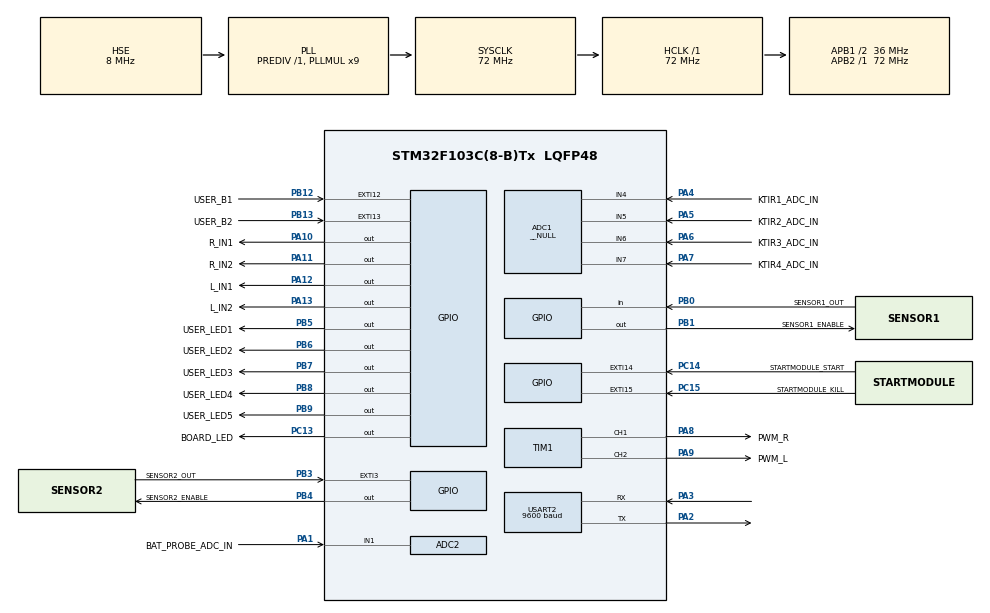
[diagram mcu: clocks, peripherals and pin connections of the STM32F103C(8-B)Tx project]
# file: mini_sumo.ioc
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Mcu.Family=STM32F1
ADC1.ContinuousConvMode=ENABLE
ADC2.Channel-0\#ChannelRegularConversion=ADC_CHANNEL_1
PA6.GPIO_Label=KTIR3_ADC_IN
PB0.GPIO_Label=SENSOR1_OUT
PB6.GPIO_Label=USER_LED2
PB13.GPIO_Label=USER_B2
PB13.Signal=GPXTI13
PC15-OSC32_OUT.GPIO_Label=STARTMODULE_KILL
RCC.SYSCLKSource=RCC_SYSCLKSOURCE_PLLCLK
ProjectManager.StackSize=0x400
PD1-OSC_OUT.Signal=RCC_OSC_OUT
PA12.Signal=GPIO_Output
ADC1.Mode=__NULL
RCC.HCLKFreq_Value=72000000
RCC.APB2TimFreq_Value=72000000
PB6.Signal=GPIO_Output
Dma.ADC1.0.Direction=DMA_PERIPH_TO_MEMORY
Dma.ADC1.0.MemDataAlignment=DMA_MDATAALIGN_HALFWORD
RCC.AHBFreq_Value=72000000
RCC.PLLMUL=RCC_PLL_MUL9
PB12.GPIO_Label=USER_B1
TIM1.Channel-PWM\ Generation1\ CH1=TIM_CHANNEL_1
PB1.GPIO_Label=SENSOR1_ENABLE
Dma.ADC1.0.PeriphInc=DMA_PINC_DISABLE
PA10.GPIO_Label=R_IN1
PB7.Signal=GPIO_Output
PA8.Signal=S_TIM1_CH1
PB7.GPIO_Label=USER_LED3
Mcu.Package=LQFP48
PB9.Signal=GPIO_Output
PB1.Signal=GPIO_Output
PA6.Signal=ADCx_IN6
USART2.VirtualMode=VM_ASYNC
PA10.Signal=GPIO_Output
ADC2.SamplingTime-0\#ChannelRegularConversion=ADC_SAMPLETIME_1CYCLE_5
SH.ADCx_IN1.0=ADC2_IN1,IN1
PB5.GPIO_Label=USER_LED1
RCC.APB1TimFreq_Value=72000000
PC14-OSC32_IN.GPIO_Label=STARTMODULE_START
ADC2.Rank-0\#ChannelRegularConversion=1
Dma.Request0=ADC1
PA4.GPIO_Label=KTIR1_ADC_IN
PB4.Signal=GPIO_Output
PA3.Signal=USART2_RX
PB3.GPIO_Label=SENSOR2_OUT
RCC.PLLSourceVirtual=RCC_PLLSOURCE_HSE
Dma.ADC1.0.Instance=DMA1_Channel1
PD1-OSC_OUT.Mode=HSE-External-Oscillator
PB9.GPIO_Label=USER_LED5
SH.ADCx_IN6.0=ADC1_IN6,IN6
PA9.GPIO_Label=PWM_L
PC13-TAMPER-RTC.Signal=GPIO_Output
PA11.GPIO_Label=R_IN2
PD0-OSC_IN.Signal=RCC_OSC_IN
RCC.APB1CLKDivider=RCC_HCLK_DIV2
PC14-OSC32_IN.Signal=GPXTI14
VP_SYS_VS_ND.Mode=No_Debug
NVIC.USART2_IRQn=true\:0\:0\:false\:false\:true\:true\:true
USART2.BaudRate=9600
PA12.GPIO_Label=L_IN1
RCC.ADCPresc=RCC_ADCPCLK2_DIV6
PA3.Mode=Asynchronous
PA13.Signal=GPIO_Output
PB8.GPIO_Label=USER_LED4
Dma.ADC1.0.PeriphDataAlignment=DMA_PDATAALIGN_HALFWORD
PA8.GPIO_Label=PWM_R
SH.S_TIM1_CH1.0=TIM1_CH1,PWM Generation1 CH1
ProjectManager.TargetToolchain=STM32CubeIDE
SH.ADCx_IN7.0=ADC1_IN7,IN7
Dma.ADC1.0.Mode=DMA_CIRCULAR
Dma.ADC1.0.Priority=DMA_PRIORITY_LOW
PA9.Signal=S_TIM1_CH2
ADC1.Channel-1\#ChannelRegularConversion=ADC_CHANNEL_4
TIM1.Channel-PWM\ Generation2\ CH2=TIM_CHANNEL_2
RCC.USBFreq_Value=72000000
PC15-OSC32_OUT.Signal=GPXTI15
PA1.Signal=ADCx_IN1
PD0-OSC_IN.Mode=HSE-External-Oscillator
PA5.Signal=ADCx_IN5
board=custom
PC13-TAMPER-RTC.GPIO_Label=BOARD_LED
RCC.APB2Freq_Value=72000000
PB4.GPIO_Label=SENSOR2_ENABLE
SH.S_TIM1_CH2.0=TIM1_CH2,PWM Generation2 CH2
PA1.GPIO_Label=BAT_PROBE_ADC_IN
SH.ADCx_IN4.0=ADC1_IN4,IN4
ADC1.NbrOfConversion=1
Mcu.Name=STM32F103C(8-B)Tx
PA2.Signal=USART2_TX
PA13.GPIO_Label=L_IN2
PB3.Signal=GPXTI3
PA4.Signal=ADCx_IN4
ADC1.SamplingTime-1\#ChannelRegularConversion=ADC_SAMPLETIME_239CYCLES_5
RCC.SYSCLKFreq_VALUE=72000000
PB5.Signal=GPIO_Output
PA7.GPIO_Label=KTIR4_ADC_IN
ADC1.master=1
PA5.GPIO_Label=KTIR2_ADC_IN
ADC2.NbrOfConversionFlag=1
ADC1.Rank-1\#ChannelRegularConversion=1
PA11.Signal=GPIO_Output
Dma.ADC1.0.MemInc=DMA_MINC_ENABLE
ProjectManager.HeapSize=0x200
SH.ADCx_IN5.0=ADC1_IN5,IN5
NVIC.PriorityGroup=NVIC_PRIORITYGROUP_4
ADC1.NbrOfConversionFlag=1
PA2.Mode=Asynchronous
PB8.Signal=GPIO_Output
NVIC.DMA1_Channel1_IRQn=true\:0\:0\:false\:false\:true\:false\:true
RCC.APB1Freq_Value=36000000
PB0.Signal=GPIO_Input
PB12.Signal=GPXTI12
PB0.GPIO_PuPd=GPIO_PULLUP
PA7.Signal=ADCx_IN7

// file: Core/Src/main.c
/* USER CODE BEGIN Header */
/**
  ******************************************************************************
  * @file           : main.c
  * @brief          : Main program body
  ******************************************************************************
  * @attention
  *
  * <h2><center>&copy; Copyright (c) 2021 STMicroelectronics.
  * All rights reserved.</center></h2>
  *
  * This software component is licensed by ST under BSD 3-Clause license,
  * the "License"; You may not use this file except in compliance with the
  * License. You may obtain a copy of the License at:
  *                        opensource.org/licenses/BSD-3-Clause
  *
  ******************************************************************************
  */
/* USER CODE END Header */
#include "main.h"

/* USER CODE BEGIN Includes */

#include <stdio.h>

/* USER CODE END Includes */

ADC_HandleTypeDef hadc1;
ADC_HandleTypeDef hadc2;
DMA_HandleTypeDef hdma_adc1;

TIM_HandleTypeDef htim1;

UART_HandleTypeDef huart2;

void SystemClock_Config(void);
static void MX_GPIO_Init(void);
static void MX_DMA_Init(void);
static void MX_ADC1_Init(void);
static void MX_USART2_UART_Init(void);
static void MX_TIM1_Init(void);
static void MX_ADC2_Init(void);
/* USER CODE BEGIN PFP */

int
_write(int file, uint8_t *ptr, int len) {
	HAL_UART_Transmit_IT(&huart2, ptr, len);
	return len;
}

/* USER CODE END PFP */

int main(void)
{

  /* MCU Configuration--------------------------------------------------------*/

  /* Reset of all peripherals, Initializes the Flash interface and the Systick. */
  HAL_Init();

  /* Configure the system clock */
  SystemClock_Config();

  /* Initialize all configured peripherals */
  MX_GPIO_Init();
  MX_DMA_Init();
  MX_ADC1_Init();
  MX_USART2_UART_Init();
  MX_TIM1_Init();
  MX_ADC2_Init();
  /* USER CODE BEGIN 2 */
  HAL_GPIO_WritePin(SENSOR1_ENABLE_GPIO_Port, SENSOR1_ENABLE_Pin, 1);
  uint8_t flag = 0;
  /* USER CODE END 2 */

  /* Infinite loop */
  /* USER CODE BEGIN WHILE */
  while (1)
  {

	  if (HAL_GPIO_ReadPin(SENSOR1_OUT_GPIO_Port, SENSOR1_OUT_Pin) == 0) {
		  flag = 1;
	  }

	  HAL_Delay(1000);
	  if (flag) {
	  HAL_GPIO_TogglePin(BOARD_LED_GPIO_Port, BOARD_LED_Pin);
	  }

    /* USER CODE END WHILE */

  }
}

void SystemClock_Config(void)
{
  RCC_OscInitTypeDef RCC_OscInitStruct = {0};
  RCC_ClkInitTypeDef RCC_ClkInitStruct = {0};
  RCC_PeriphCLKInitTypeDef PeriphClkInit = {0};

  /** Initializes the RCC Oscillators according to the specified parameters
  * in the RCC_OscInitTypeDef structure.
  */
  RCC_OscInitStruct.OscillatorType = RCC_OSCILLATORTYPE_HSE;
  RCC_OscInitStruct.HSEState = RCC_HSE_ON;
  RCC_OscInitStruct.HSEPredivValue = RCC_HSE_PREDIV_DIV1;
  RCC_OscInitStruct.HSIState = RCC_HSI_ON;
  RCC_OscInitStruct.PLL.PLLState = RCC_PLL_ON;
  RCC_OscInitStruct.PLL.PLLSource = RCC_PLLSOURCE_HSE;
  RCC_OscInitStruct.PLL.PLLMUL = RCC_PLL_MUL9;
  if (HAL_RCC_OscConfig(&RCC_OscInitStruct) != HAL_OK)
  {
    Error_Handler();
  }
  /** Initializes the CPU, AHB and APB buses clocks
  */
  RCC_ClkInitStruct.ClockType = RCC_CLOCKTYPE_HCLK|RCC_CLOCKTYPE_SYSCLK
                              |RCC_CLOCKTYPE_PCLK1|RCC_CLOCKTYPE_PCLK2;
  RCC_ClkInitStruct.SYSCLKSource = RCC_SYSCLKSOURCE_PLLCLK;
  RCC_ClkInitStruct.AHBCLKDivider = RCC_SYSCLK_DIV1;
  RCC_ClkInitStruct.APB1CLKDivider = RCC_HCLK_DIV2;
  RCC_ClkInitStruct.APB2CLKDivider = RCC_HCLK_DIV1;

  if (HAL_RCC_ClockConfig(&RCC_ClkInitStruct, FLASH_LATENCY_2) != HAL_OK)
  {
    Error_Handler();
  }
  PeriphClkInit.PeriphClockSelection = RCC_PERIPHCLK_ADC;
  PeriphClkInit.AdcClockSelection = RCC_ADCPCLK2_DIV6;
  if (HAL_RCCEx_PeriphCLKConfig(&PeriphClkInit) != HAL_OK)
  {
    Error_Handler();
  }
}

static void MX_ADC1_Init(void)
{

  ADC_ChannelConfTypeDef sConfig = {0};

  /** Common config
  */
  hadc1.Instance = ADC1;
  hadc1.Init.ScanConvMode = ADC_SCAN_DISABLE;
  hadc1.Init.ContinuousConvMode = ENABLE;
  hadc1.Init.DiscontinuousConvMode = DISABLE;
  hadc1.Init.ExternalTrigConv = ADC_SOFTWARE_START;
  hadc1.Init.DataAlign = ADC_DATAALIGN_RIGHT;
  hadc1.Init.NbrOfConversion = 1;
  if (HAL_ADC_Init(&hadc1) != HAL_OK)
  {
    Error_Handler();
  }
  /** Configure Regular Channel
  */
  sConfig.Channel = ADC_CHANNEL_4;
  sConfig.Rank = ADC_REGULAR_RANK_1;
  sConfig.SamplingTime = ADC_SAMPLETIME_239CYCLES_5;
  if (HAL_ADC_ConfigChannel(&hadc1, &sConfig) != HAL_OK)
  {
    Error_Handler();
  }

}

static void MX_ADC2_Init(void)
{

  ADC_ChannelConfTypeDef sConfig = {0};

  /** Common config
  */
  hadc2.Instance = ADC2;
  hadc2.Init.ScanConvMode = ADC_SCAN_DISABLE;
  hadc2.Init.ContinuousConvMode = DISABLE;
  hadc2.Init.DiscontinuousConvMode = DISABLE;
  hadc2.Init.ExternalTrigConv = ADC_SOFTWARE_START;
  hadc2.Init.DataAlign = ADC_DATAALIGN_RIGHT;
  hadc2.Init.NbrOfConversion = 1;
  if (HAL_ADC_Init(&hadc2) != HAL_OK)
  {
    Error_Handler();
  }
  /** Configure Regular Channel
  */
  sConfig.Channel = ADC_CHANNEL_1;
  sConfig.Rank = ADC_REGULAR_RANK_1;
  sConfig.SamplingTime = ADC_SAMPLETIME_1CYCLE_5;
  if (HAL_ADC_ConfigChannel(&hadc2, &sConfig) != HAL_OK)
  {
    Error_Handler();
  }

}

static void MX_TIM1_Init(void)
{

  TIM_MasterConfigTypeDef sMasterConfig = {0};
  TIM_OC_InitTypeDef sConfigOC = {0};
  TIM_BreakDeadTimeConfigTypeDef sBreakDeadTimeConfig = {0};

  htim1.Instance = TIM1;
  htim1.Init.Prescaler = 0;
  htim1.Init.CounterMode = TIM_COUNTERMODE_UP;
  htim1.Init.Period = 65535;
  htim1.Init.ClockDivision = TIM_CLOCKDIVISION_DIV1;
  htim1.Init.RepetitionCounter = 0;
  htim1.Init.AutoReloadPreload = TIM_AUTORELOAD_PRELOAD_DISABLE;
  if (HAL_TIM_PWM_Init(&htim1) != HAL_OK)
  {
    Error_Handler();
  }
  sMasterConfig.MasterOutputTrigger = TIM_TRGO_RESET;
  sMasterConfig.MasterSlaveMode = TIM_MASTERSLAVEMODE_DISABLE;
  if (HAL_TIMEx_MasterConfigSynchronization(&htim1, &sMasterConfig) != HAL_OK)
  {
    Error_Handler();
  }
  sConfigOC.OCMode = TIM_OCMODE_PWM1;
  sConfigOC.Pulse = 0;
  sConfigOC.OCPolarity = TIM_OCPOLARITY_HIGH;
  sConfigOC.OCNPolarity = TIM_OCNPOLARITY_HIGH;
  sConfigOC.OCFastMode = TIM_OCFAST_DISABLE;
  sConfigOC.OCIdleState = TIM_OCIDLESTATE_RESET;
  sConfigOC.OCNIdleState = TIM_OCNIDLESTATE_RESET;
  if (HAL_TIM_PWM_ConfigChannel(&htim1, &sConfigOC, TIM_CHANNEL_1) != HAL_OK)
  {
    Error_Handler();
  }
  if (HAL_TIM_PWM_ConfigChannel(&htim1, &sConfigOC, TIM_CHANNEL_2) != HAL_OK)
  {
    Error_Handler();
  }
  sBreakDeadTimeConfig.OffStateRunMode = TIM_OSSR_DISABLE;
  sBreakDeadTimeConfig.OffStateIDLEMode = TIM_OSSI_DISABLE;
  sBreakDeadTimeConfig.LockLevel = TIM_LOCKLEVEL_OFF;
  sBreakDeadTimeConfig.DeadTime = 0;
  sBreakDeadTimeConfig.BreakState = TIM_BREAK_DISABLE;
  sBreakDeadTimeConfig.BreakPolarity = TIM_BREAKPOLARITY_HIGH;
  sBreakDeadTimeConfig.AutomaticOutput = TIM_AUTOMATICOUTPUT_DISABLE;
  if (HAL_TIMEx_ConfigBreakDeadTime(&htim1, &sBreakDeadTimeConfig) != HAL_OK)
  {
    Error_Handler();
  }
  HAL_TIM_MspPostInit(&htim1);

}

static void MX_USART2_UART_Init(void)
{

  huart2.Instance = USART2;
  huart2.Init.BaudRate = 9600;
  huart2.Init.WordLength = UART_WORDLENGTH_8B;
  huart2.Init.StopBits = UART_STOPBITS_1;
  huart2.Init.Parity = UART_PARITY_NONE;
  huart2.Init.Mode = UART_MODE_TX_RX;
  huart2.Init.HwFlowCtl = UART_HWCONTROL_NONE;
  huart2.Init.OverSampling = UART_OVERSAMPLING_16;
  if (HAL_UART_Init(&huart2) != HAL_OK)
  {
    Error_Handler();
  }

}

static void MX_DMA_Init(void)
{

  /* DMA controller clock enable */
  __HAL_RCC_DMA1_CLK_ENABLE();

  /* DMA interrupt init */
  /* DMA1_Channel1_IRQn interrupt configuration */
  HAL_NVIC_SetPriority(DMA1_Channel1_IRQn, 0, 0);
  HAL_NVIC_EnableIRQ(DMA1_Channel1_IRQn);

}

static void MX_GPIO_Init(void)
{
  GPIO_InitTypeDef GPIO_InitStruct = {0};

  /* GPIO Ports Clock Enable */
  __HAL_RCC_GPIOC_CLK_ENABLE();
  __HAL_RCC_GPIOD_CLK_ENABLE();
  __HAL_RCC_GPIOA_CLK_ENABLE();
  __HAL_RCC_GPIOB_CLK_ENABLE();

  /*Configure GPIO pin Output Level */
  HAL_GPIO_WritePin(BOARD_LED_GPIO_Port, BOARD_LED_Pin, GPIO_PIN_RESET);

  /*Configure GPIO pin Output Level */
  HAL_GPIO_WritePin(GPIOB, SENSOR1_ENABLE_Pin|SENSOR2_ENABLE_Pin|USER_LED1_Pin|USER_LED2_Pin
                          |USER_LED3_Pin|USER_LED4_Pin|USER_LED5_Pin, GPIO_PIN_RESET);

  /*Configure GPIO pin Output Level */
  HAL_GPIO_WritePin(GPIOA, R_IN1_Pin|R_IN2_Pin|L_IN1_Pin|L_IN2_Pin, GPIO_PIN_RESET);

  /*Configure GPIO pin : BOARD_LED_Pin */
  GPIO_InitStruct.Pin = BOARD_LED_Pin;
  GPIO_InitStruct.Mode = GPIO_MODE_OUTPUT_PP;
  GPIO_InitStruct.Pull = GPIO_NOPULL;
  GPIO_InitStruct.Speed = GPIO_SPEED_FREQ_LOW;
  HAL_GPIO_Init(BOARD_LED_GPIO_Port, &GPIO_InitStruct);

  /*Configure GPIO pins : STARTMODULE_START_Pin STARTMODULE_KILL_Pin */
  GPIO_InitStruct.Pin = STARTMODULE_START_Pin|STARTMODULE_KILL_Pin;
  GPIO_InitStruct.Mode = GPIO_MODE_IT_RISING;
  GPIO_InitStruct.Pull = GPIO_NOPULL;
  HAL_GPIO_Init(GPIOC, &GPIO_InitStruct);

  /*Configure GPIO pin : SENSOR1_OUT_Pin */
  GPIO_InitStruct.Pin = SENSOR1_OUT_Pin;
  GPIO_InitStruct.Mode = GPIO_MODE_INPUT;
  GPIO_InitStruct.Pull = GPIO_PULLUP;
  HAL_GPIO_Init(SENSOR1_OUT_GPIO_Port, &GPIO_InitStruct);

  /*Configure GPIO pins : SENSOR1_ENABLE_Pin SENSOR2_ENABLE_Pin USER_LED1_Pin USER_LED2_Pin
                           USER_LED3_Pin USER_LED4_Pin USER_LED5_Pin */
  GPIO_InitStruct.Pin = SENSOR1_ENABLE_Pin|SENSOR2_ENABLE_Pin|USER_LED1_Pin|USER_LED2_Pin
                          |USER_LED3_Pin|USER_LED4_Pin|USER_LED5_Pin;
  GPIO_InitStruct.Mode = GPIO_MODE_OUTPUT_PP;
  GPIO_InitStruct.Pull = GPIO_NOPULL;
  GPIO_InitStruct.Speed = GPIO_SPEED_FREQ_LOW;
  HAL_GPIO_Init(GPIOB, &GPIO_InitStruct);

  /*Configure GPIO pins : USER_B1_Pin USER_B2_Pin SENSOR2_OUT_Pin */
  GPIO_InitStruct.Pin = USER_B1_Pin|USER_B2_Pin|SENSOR2_OUT_Pin;
  GPIO_InitStruct.Mode = GPIO_MODE_IT_RISING;
  GPIO_InitStruct.Pull = GPIO_NOPULL;
  HAL_GPIO_Init(GPIOB, &GPIO_InitStruct);

  /*Configure GPIO pins : R_IN1_Pin R_IN2_Pin L_IN1_Pin L_IN2_Pin */
  GPIO_InitStruct.Pin = R_IN1_Pin|R_IN2_Pin|L_IN1_Pin|L_IN2_Pin;
  GPIO_InitStruct.Mode = GPIO_MODE_OUTPUT_PP;
  GPIO_InitStruct.Pull = GPIO_NOPULL;
  GPIO_InitStruct.Speed = GPIO_SPEED_FREQ_LOW;
  HAL_GPIO_Init(GPIOA, &GPIO_InitStruct);

}

void Error_Handler(void)
{
}

/************************ (C) COPYRIGHT STMicroelectronics *****END OF FILE****/
